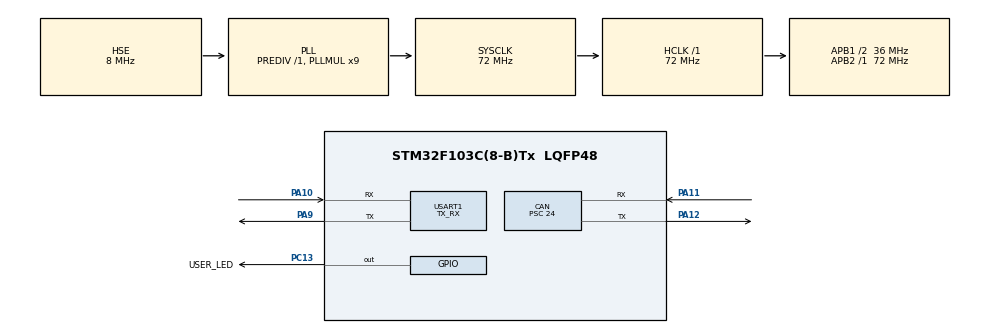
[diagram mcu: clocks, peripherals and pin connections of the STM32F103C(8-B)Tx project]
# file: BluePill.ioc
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Mcu.Family=STM32F1
RCC.PLLSourceVirtual=RCC_PLLSOURCE_HSE
NVIC.CAN1_RX1_IRQn=true\:0\:0\:false\:false\:true\:true\:true
Dma.USART1_TX.0.MemInc=DMA_MINC_ENABLE
PD1-OSC_OUT.Mode=HSE-External-Oscillator
Dma.USART1_TX.0.PeriphInc=DMA_PINC_DISABLE
PA10.Mode=Asynchronous
CAN.ABOM=ENABLE
PA10.GPIO_PuPd=GPIO_PULLUP
CAN.CalculateBaudRate=187500
PC13-TAMPER-RTC.Signal=GPIO_Output
PA11.Mode=CAN_Activate
PD0-OSC_IN.Signal=RCC_OSC_IN
RCC.APB1CLKDivider=RCC_HCLK_DIV2
CAN.CalculateTimeBit=5333.33
RCC.SYSCLKSource=RCC_SYSCLKSOURCE_PLLCLK
ProjectManager.StackSize=0x400
PD1-OSC_OUT.Signal=RCC_OSC_OUT
PA13.Signal=SYS_JTMS-SWDIO
Dma.USART1_TX.0.Priority=DMA_PRIORITY_LOW
PA9.Mode=Asynchronous
PA12.Signal=CAN_TX
CAN.BS1=CAN_BS1_6TQ
CAN.Prescaler=24
Dma.USART1_TX.0.Direction=DMA_MEMORY_TO_PERIPH
ProjectManager.TargetToolchain=STM32CubeIDE
RCC.HCLKFreq_Value=72000000
RCC.APB2TimFreq_Value=72000000
PA9.Signal=USART1_TX
RCC.USBFreq_Value=72000000
CAN.Mode=CAN_MODE_LOOPBACK
RCC.AHBFreq_Value=72000000
PD0-OSC_IN.Mode=HSE-External-Oscillator
Dma.USART1_TX.0.Mode=DMA_NORMAL
board=custom
PC13-TAMPER-RTC.GPIO_Label=USER_LED
RCC.PLLMUL=RCC_PLL_MUL9
RCC.APB2Freq_Value=72000000
PC13-TAMPER-RTC.PinState=GPIO_PIN_SET
USART1.Mode=MODE_TX_RX
PA14.Mode=Serial_Wire
NVIC.USB_LP_CAN1_RX0_IRQn=true\:0\:0\:false\:false\:true\:true\:true
CAN.NART=ENABLE
PA13.Mode=Serial_Wire
Dma.USART1_TX.0.PeriphDataAlignment=DMA_PDATAALIGN_BYTE
Mcu.Name=STM32F103C(8-B)Tx
CAN.CalculateTimeQuantum=666.6666666666667
RCC.SYSCLKFreq_VALUE=72000000
Mcu.Package=LQFP48
NVIC.TimeBase=TIM4_IRQn
PA12.Mode=CAN_Activate
USART1.VirtualMode=VM_ASYNC
PA11.Signal=CAN_RX
Dma.USART1_TX.0.MemDataAlignment=DMA_MDATAALIGN_BYTE
NVIC.TimeBaseIP=TIM4
PA10.Signal=USART1_RX
PA14.Signal=SYS_JTCK-SWCLK
ProjectManager.HeapSize=0x200
Dma.USART1_TX.0.Instance=DMA1_Channel4
VP_SYS_VS_tim4.Mode=TIM4
NVIC.PriorityGroup=NVIC_PRIORITYGROUP_4
RCC.APB1TimFreq_Value=72000000
CAN.AWUM=ENABLE
NVIC.DMA1_Channel4_IRQn=true\:0\:0\:false\:false\:true\:false\:true
NVIC.USART1_IRQn=true\:0\:0\:false\:false\:true\:true\:true
NVIC.TIM4_IRQn=true\:0\:0\:false\:false\:true\:false\:true
Dma.Request0=USART1_TX
RCC.APB1Freq_Value=36000000

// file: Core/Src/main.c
/* USER CODE BEGIN Header */
/**
  ******************************************************************************
  * @file           : main.c
  * @brief          : Main program body
  ******************************************************************************
  * @attention
  *
  * <h2><center>&copy; Copyright (c) 2021 STMicroelectronics.
  * All rights reserved.</center></h2>
  *
  * This software component is licensed by ST under BSD 3-Clause license,
  * the "License"; You may not use this file except in compliance with the
  * License. You may obtain a copy of the License at:
  *                        opensource.org/licenses/BSD-3-Clause
  *
  ******************************************************************************
  */
/* USER CODE END Header */
#include "main.h"

CAN_HandleTypeDef hcan;

UART_HandleTypeDef huart1;
DMA_HandleTypeDef hdma_usart1_tx;

void SystemClock_Config(void);
static void MX_GPIO_Init(void);
static void MX_DMA_Init(void);
static void MX_USART1_UART_Init(void);
static void MX_CAN_Init(void);

int main(void)
{

  /* MCU Configuration--------------------------------------------------------*/

  /* Reset of all peripherals, Initializes the Flash interface and the Systick. */
  HAL_Init();

  /* Configure the system clock */
  SystemClock_Config();

  /* Initialize all configured peripherals */
  MX_GPIO_Init();
  MX_DMA_Init();
  MX_USART1_UART_Init();
  MX_CAN_Init();
  /* USER CODE BEGIN 2 */
  PollingInit();
  /* USER CODE END 2 */

  /* Infinite loop */
  /* USER CODE BEGIN WHILE */
  while (1)
  {
	  PollingRoutine();
    /* USER CODE END WHILE */

  }
}

void SystemClock_Config(void)
{
  RCC_OscInitTypeDef RCC_OscInitStruct = {0};
  RCC_ClkInitTypeDef RCC_ClkInitStruct = {0};

  /** Initializes the RCC Oscillators according to the specified parameters
  * in the RCC_OscInitTypeDef structure.
  */
  RCC_OscInitStruct.OscillatorType = RCC_OSCILLATORTYPE_HSE;
  RCC_OscInitStruct.HSEState = RCC_HSE_ON;
  RCC_OscInitStruct.HSEPredivValue = RCC_HSE_PREDIV_DIV1;
  RCC_OscInitStruct.HSIState = RCC_HSI_ON;
  RCC_OscInitStruct.PLL.PLLState = RCC_PLL_ON;
  RCC_OscInitStruct.PLL.PLLSource = RCC_PLLSOURCE_HSE;
  RCC_OscInitStruct.PLL.PLLMUL = RCC_PLL_MUL9;
  if (HAL_RCC_OscConfig(&RCC_OscInitStruct) != HAL_OK)
  {
    Error_Handler();
  }
  /** Initializes the CPU, AHB and APB buses clocks
  */
  RCC_ClkInitStruct.ClockType = RCC_CLOCKTYPE_HCLK|RCC_CLOCKTYPE_SYSCLK
                              |RCC_CLOCKTYPE_PCLK1|RCC_CLOCKTYPE_PCLK2;
  RCC_ClkInitStruct.SYSCLKSource = RCC_SYSCLKSOURCE_PLLCLK;
  RCC_ClkInitStruct.AHBCLKDivider = RCC_SYSCLK_DIV1;
  RCC_ClkInitStruct.APB1CLKDivider = RCC_HCLK_DIV2;
  RCC_ClkInitStruct.APB2CLKDivider = RCC_HCLK_DIV1;

  if (HAL_RCC_ClockConfig(&RCC_ClkInitStruct, FLASH_LATENCY_2) != HAL_OK)
  {
    Error_Handler();
  }
}

static void MX_CAN_Init(void)
{

  hcan.Instance = CAN1;
  hcan.Init.Prescaler = 24;
  hcan.Init.Mode = CAN_MODE_LOOPBACK;
  hcan.Init.SyncJumpWidth = CAN_SJW_1TQ;
  hcan.Init.TimeSeg1 = CAN_BS1_6TQ;
  hcan.Init.TimeSeg2 = CAN_BS2_1TQ;
  hcan.Init.TimeTriggeredMode = DISABLE;
  hcan.Init.AutoBusOff = ENABLE;
  hcan.Init.AutoWakeUp = ENABLE;
  hcan.Init.AutoRetransmission = ENABLE;
  hcan.Init.ReceiveFifoLocked = DISABLE;
  hcan.Init.TransmitFifoPriority = DISABLE;
  if (HAL_CAN_Init(&hcan) != HAL_OK)
  {
    Error_Handler();
  }

}

static void MX_USART1_UART_Init(void)
{

  huart1.Instance = USART1;
  huart1.Init.BaudRate = 115200;
  huart1.Init.WordLength = UART_WORDLENGTH_8B;
  huart1.Init.StopBits = UART_STOPBITS_1;
  huart1.Init.Parity = UART_PARITY_NONE;
  huart1.Init.Mode = UART_MODE_TX_RX;
  huart1.Init.HwFlowCtl = UART_HWCONTROL_NONE;
  huart1.Init.OverSampling = UART_OVERSAMPLING_16;
  if (HAL_UART_Init(&huart1) != HAL_OK)
  {
    Error_Handler();
  }

}

static void MX_DMA_Init(void)
{

  /* DMA controller clock enable */
  __HAL_RCC_DMA1_CLK_ENABLE();

  /* DMA interrupt init */
  /* DMA1_Channel4_IRQn interrupt configuration */
  HAL_NVIC_SetPriority(DMA1_Channel4_IRQn, 0, 0);
  HAL_NVIC_EnableIRQ(DMA1_Channel4_IRQn);

}

static void MX_GPIO_Init(void)
{
  GPIO_InitTypeDef GPIO_InitStruct = {0};

  /* GPIO Ports Clock Enable */
  __HAL_RCC_GPIOC_CLK_ENABLE();
  __HAL_RCC_GPIOD_CLK_ENABLE();
  __HAL_RCC_GPIOA_CLK_ENABLE();

  /*Configure GPIO pin Output Level */
  HAL_GPIO_WritePin(USER_LED_GPIO_Port, USER_LED_Pin, GPIO_PIN_SET);

  /*Configure GPIO pin : USER_LED_Pin */
  GPIO_InitStruct.Pin = USER_LED_Pin;
  GPIO_InitStruct.Mode = GPIO_MODE_OUTPUT_PP;
  GPIO_InitStruct.Pull = GPIO_NOPULL;
  GPIO_InitStruct.Speed = GPIO_SPEED_FREQ_LOW;
  HAL_GPIO_Init(USER_LED_GPIO_Port, &GPIO_InitStruct);

}

 /**
  * @brief  Period elapsed callback in non blocking mode
  * @note   This function is called  when TIM4 interrupt took place, inside
  * HAL_TIM_IRQHandler(). It makes a direct call to HAL_IncTick() to increment
  * a global variable "uwTick" used as application time base.
  * @param  htim : TIM handle
  * @retval None
  */
void HAL_TIM_PeriodElapsedCallback(TIM_HandleTypeDef *htim)
{
  if (htim->Instance == TIM4) {
    HAL_IncTick();
  }
  /* USER CODE BEGIN Callback 1 */
  if (htim->Instance == TIM4) {
    TimerCallbackIncrement();
  }
  /* USER CODE END Callback 1 */
}

void Error_Handler(void)
{
  __disable_irq();
  while (1)
  {
  }
}

/************************ (C) COPYRIGHT STMicroelectronics *****END OF FILE****/
